VERSION ""
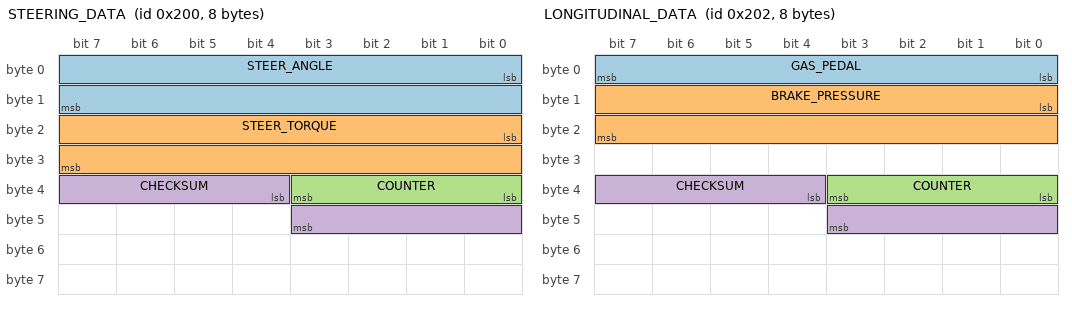
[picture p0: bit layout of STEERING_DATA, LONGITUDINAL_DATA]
BO_ 512 STEERING_DATA: 8 EPS
 SG_ STEER_ANGLE : 0|16@1- (0.1,0) [-360|360] "deg" Vector__XXX
 SG_ STEER_TORQUE : 16|16@1- (0.01,0) [-10|10] "Nm" Vector__XXX
 SG_ COUNTER : 32|4@1+ (1,0) [0|15] "" Vector__XXX
 SG_ CHECKSUM : 36|8@1+ (1,0) [0|255] "" Vector__XXX
BO_ 514 LONGITUDINAL_DATA: 8 PCM
 SG_ GAS_PEDAL : 0|8@1+ (0.392,0) [0|100] "%" Vector__XXX
 SG_ BRAKE_PRESSURE : 8|16@1+ (1,0) [0|5000] "bar" Vector__XXX
 SG_ COUNTER : 32|4@1+ (1,0) [0|15] "" Vector__XXX
 SG_ CHECKSUM : 36|8@1+ (1,0) [0|255] "" Vector__XXX
